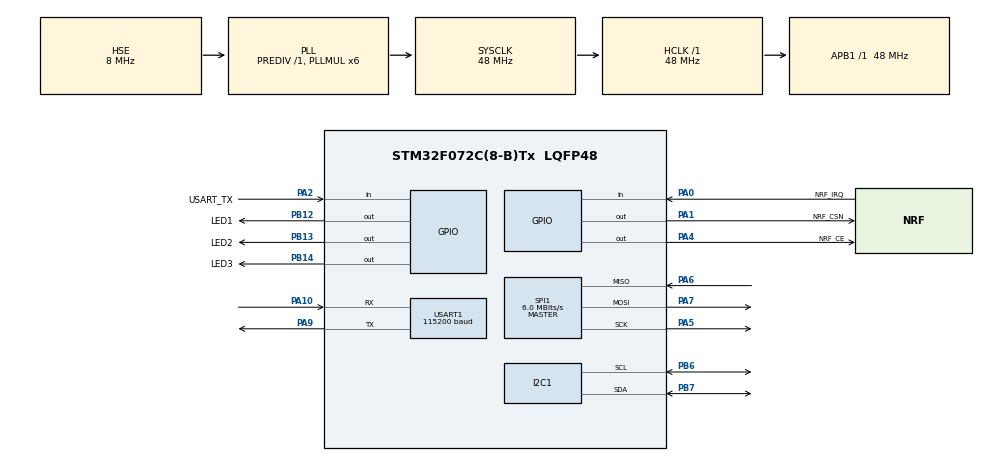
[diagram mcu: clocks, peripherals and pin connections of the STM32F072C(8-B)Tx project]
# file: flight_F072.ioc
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I2C1.Timing=0x20303E5D
Mcu.Family=STM32F0
Mcu.Name=STM32F072C(8-B)Tx
Mcu.Package=LQFP48
NVIC.TIM2_IRQn=true\:1\:0\:true\:false\:true\:true
NVIC.TIM7_IRQn=true\:1\:0\:true\:false\:true\:true
PA0.GPIO_Label=NRF_IRQ
PA0.GPIO_PuPd=GPIO_PULLUP
PA0.Signal=GPIO_Input
PA1.GPIO_Label=NRF_CSN
PA1.GPIO_ModeDefaultOutputPP=GPIO_MODE_OUTPUT_PP
PA1.GPIO_PuPd=GPIO_PULLUP
PA1.GPIO_Speed=GPIO_SPEED_FREQ_HIGH
PA1.PinState=GPIO_PIN_SET
PA1.Signal=GPIO_Output
PA10.Mode=Asynchronous
PA10.Signal=USART1_RX
PA13.Mode=Serial_Wire
PA13.Signal=SYS_SWDIO
PA14.Mode=Serial_Wire
PA14.Signal=SYS_SWCLK
PA2.GPIO_Label=USART_TX
PA2.GPIO_PuPd=GPIO_PULLUP
PA2.Signal=GPIO_Input
PA4.GPIO_Label=NRF_CE
PA4.GPIO_ModeDefaultOutputPP=GPIO_MODE_OUTPUT_PP
PA4.GPIO_PuPd=GPIO_PULLUP
PA4.GPIO_Speed=GPIO_SPEED_FREQ_HIGH
PA4.PinState=GPIO_PIN_SET
PA4.Signal=GPIO_Output
PA5.Mode=Full_Duplex_Master
PA5.Signal=SPI1_SCK
PA6.Mode=Full_Duplex_Master
PA6.Signal=SPI1_MISO
PA7.Mode=Full_Duplex_Master
PA7.Signal=SPI1_MOSI
PA9.Mode=Asynchronous
PA9.Signal=USART1_TX
PB12.GPIO_Label=LED1
PB12.GPIO_PuPd=GPIO_PULLUP
PB12.GPIO_Speed=GPIO_SPEED_FREQ_HIGH
PB12.PinState=GPIO_PIN_SET
PB12.Signal=GPIO_Output
PB13.GPIO_Label=LED2
PB13.GPIO_PuPd=GPIO_PULLUP
PB13.GPIO_Speed=GPIO_SPEED_FREQ_HIGH
PB13.PinState=GPIO_PIN_SET
PB13.Signal=GPIO_Output
PB14.GPIO_Label=LED3
PB14.GPIO_PuPd=GPIO_PULLUP
PB14.GPIO_Speed=GPIO_SPEED_FREQ_HIGH
PB14.PinState=GPIO_PIN_SET
PB14.Signal=GPIO_Output
PB6.GPIO_PuPdOD=GPIO_PULLUP
PB6.Mode=I2C
PB6.Signal=I2C1_SCL
PB7.GPIO_PuPdOD=GPIO_PULLUP
PB7.Mode=I2C
PB7.Signal=I2C1_SDA
PF0-OSC_IN.Mode=HSE-External-Oscillator
PF0-OSC_IN.Signal=RCC_OSC_IN
PF1-OSC_OUT.Mode=HSE-External-Oscillator
PF1-OSC_OUT.Signal=RCC_OSC_OUT
ProjectManager.HeapSize=0x200
ProjectManager.StackSize=0x400
ProjectManager.TargetToolchain=MDK-ARM V5
RCC.AHBFreq_Value=48000000
RCC.APB1Freq_Value=48000000
RCC.APB1TimFreq_Value=48000000
RCC.HCLKFreq_Value=48000000
RCC.I2c1ClockSelection=RCC_I2C1CLKSOURCE_SYSCLK
RCC.PLLMUL=RCC_PLL_MUL6
RCC.PLLSourceVirtual=RCC_PLLSOURCE_HSE
RCC.SYSCLKFreq_VALUE=48000000
RCC.SYSCLKSource=RCC_SYSCLKSOURCE_PLLCLK
SPI1.BaudRatePrescaler=SPI_BAUDRATEPRESCALER_8
SPI1.CalculateBaudRate=6.0 MBits/s
SPI1.DataSize=SPI_DATASIZE_8BIT
SPI1.Direction=SPI_DIRECTION_2LINES
SPI1.Mode=SPI_MODE_MASTER
SPI1.NSSPMode=SPI_NSS_PULSE_DISABLE
SPI1.VirtualType=VM_MASTER
TIM2.AutoReloadPreload=TIM_AUTORELOAD_PRELOAD_ENABLE
TIM2.Period=5000-1
TIM2.Prescaler=48-1
TIM7.AutoReloadPreload=TIM_AUTORELOAD_PRELOAD_ENABLE
TIM7.Period=5000-1
TIM7.Prescaler=4800-1
USART1.BaudRate=115200
USART1.VirtualMode-Asynchronous=VM_ASYNC
VP_TIM2_VS_ClockSourceINT.Mode=Internal
VP_TIM7_VS_ClockSourceINT.Mode=Enable_Timer
board=custom

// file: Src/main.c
/**
  ******************************************************************************
  * @file           : main.c
  * @brief          : Main program body
  ******************************************************************************
  ** This notice applies to any and all portions of this file
  * that are not between comment pairs USER CODE BEGIN and
  * USER CODE END. Other portions of this file, whether
  * inserted by the user or by software development tools
  * are owned by their respective copyright owners.
  *
  * COPYRIGHT(c) 2018 STMicroelectronics
  *
  * Redistribution and use in source and binary forms, with or without modification,
  * are permitted provided that the following conditions are met:
  *   1. Redistributions of source code must retain the above copyright notice,
  *      this list of conditions and the following disclaimer.
  *   2. Redistributions in binary form must reproduce the above copyright notice,
  *      this list of conditions and the following disclaimer in the documentation
  *      and/or other materials provided with the distribution.
  *   3. Neither the name of STMicroelectronics nor the names of its contributors
  *      may be used to endorse or promote products derived from this software
  *      without specific prior written permission.
  *
  * THIS SOFTWARE IS PROVIDED BY THE COPYRIGHT HOLDERS AND CONTRIBUTORS "AS IS"
  * AND ANY EXPRESS OR IMPLIED WARRANTIES, INCLUDING, BUT NOT LIMITED TO, THE
  * IMPLIED WARRANTIES OF MERCHANTABILITY AND FITNESS FOR A PARTICULAR PURPOSE ARE
  * DISCLAIMED. IN NO EVENT SHALL THE COPYRIGHT HOLDER OR CONTRIBUTORS BE LIABLE
  * FOR ANY DIRECT, INDIRECT, INCIDENTAL, SPECIAL, EXEMPLARY, OR CONSEQUENTIAL
  * DAMAGES (INCLUDING, BUT NOT LIMITED TO, PROCUREMENT OF SUBSTITUTE GOODS OR
  * SERVICES; LOSS OF USE, DATA, OR PROFITS; OR BUSINESS INTERRUPTION) HOWEVER
  * CAUSED AND ON ANY THEORY OF LIABILITY, WHETHER IN CONTRACT, STRICT LIABILITY,
  * OR TORT (INCLUDING NEGLIGENCE OR OTHERWISE) ARISING IN ANY WAY OUT OF THE USE
  * OF THIS SOFTWARE, EVEN IF ADVISED OF THE POSSIBILITY OF SUCH DAMAGE.
  *
  ******************************************************************************
  */
#include "main.h"
#include "stm32f0xx_hal.h"
#include "i2c.h"
#include "spi.h"
#include "tim.h"
#include "usart.h"
#include "gpio.h"

/* USER CODE BEGIN Includes */
#include "mpu6050.h"
#include "imu.h"
#include "24l01.h"
/* USER CODE END Includes */

/* USER CODE BEGIN PV */
/* Private variables ---------------------------------------------------------*/
extern  uint8_t Tx_buff[30] ;
/* USER CODE END PV */

void SystemClock_Config(void);

/* USER CODE BEGIN PFP */
/* Private function prototypes -----------------------------------------------*/

/* USER CODE END PFP */

/* USER CODE BEGIN 0 */
uint8_t rx_buf[10]={0}
;/* USER CODE END 0 */

int main(void)
{

  /* MCU Configuration----------------------------------------------------------*/

  /* Reset of all peripherals, Initializes the Flash interface and the Systick. */
  HAL_Init();

  /* Configure the system clock */
  SystemClock_Config();

  /* Initialize all configured peripherals */
  MX_GPIO_Init();
  MX_TIM7_Init();
  MX_TIM2_Init();
  MX_SPI1_Init();
  MX_I2C1_Init();
  MX_USART1_UART_Init();
  /* USER CODE BEGIN 2 */
  HAL_Delay(1000);
  while(mpu6050_init() != 0)
  {
    HAL_GPIO_TogglePin(LED2_GPIO_Port,LED2_Pin);
    HAL_Delay(1000);
  }
//  Get_6050_offest();
//

//  NRF24L01_Init();
//  __HAL_SPI_ENABLE(&hspi1);
//  HAL_Delay(1000);
//  while(NRF24L01_Check() != 0)
//  {
//      HAL_GPIO_WritePin(LED3_GPIO_Port,LED3_Pin,GPIO_PIN_RESET);
//      HAL_Delay(100);
//  }
//  HAL_GPIO_WritePin(LED3_GPIO_Port,LED3_Pin,GPIO_PIN_SET);
//  NRF24L01_RX_Mode();
//
//
////  HAL_TIM_Base_Start_IT(&htim2);
//  HAL_TIM_Base_Start_IT(&htim7);
//
//  Tx_buff[0] = 0xaa;
//  Tx_buff[1] = 0xab;
//  Tx_buff[2] = 0xac;
  /* USER CODE END 2 */

  /* Infinite loop */
  while (1)
  {

  /* USER CODE BEGIN 3 */
//
////        READ_MPU6050();
////        Prepare_6050_Data();
//
//    if(NRF24L01_RxPacket(Tx_buff) == 0)
//    {
//      HAL_GPIO_TogglePin(LED3_GPIO_Port,LED3_Pin);
//    }
////    if(HAL_GPIO_ReadPin(NRF_IRQ_GPIO_Port,NRF_IRQ_Pin))
////    {
////      HAL_GPIO_TogglePin(LED3_GPIO_Port,LED3_Pin);
////      HAL_Delay(1000);
////    }
    HAL_GPIO_TogglePin(LED1_GPIO_Port,LED1_Pin);
    HAL_Delay(500);
    HAL_UART_Transmit(&huart1,"transmit:\n",10,100);
    HAL_UART_Receive(&huart1,rx_buf,10,255);
    HAL_UART_Transmit(&huart1,rx_buf,10,100);
  }
  /* USER CODE END 3 */

}

void SystemClock_Config(void)
{

  RCC_OscInitTypeDef RCC_OscInitStruct;
  RCC_ClkInitTypeDef RCC_ClkInitStruct;
  RCC_PeriphCLKInitTypeDef PeriphClkInit;

    /**Initializes the CPU, AHB and APB busses clocks
    */
  RCC_OscInitStruct.OscillatorType = RCC_OSCILLATORTYPE_HSE;
  RCC_OscInitStruct.HSEState = RCC_HSE_ON;
  RCC_OscInitStruct.PLL.PLLState = RCC_PLL_ON;
  RCC_OscInitStruct.PLL.PLLSource = RCC_PLLSOURCE_HSE;
  RCC_OscInitStruct.PLL.PLLMUL = RCC_PLL_MUL6;
  RCC_OscInitStruct.PLL.PREDIV = RCC_PREDIV_DIV1;
  if (HAL_RCC_OscConfig(&RCC_OscInitStruct) != HAL_OK)
  {
    _Error_Handler(__FILE__, __LINE__);
  }

    /**Initializes the CPU, AHB and APB busses clocks
    */
  RCC_ClkInitStruct.ClockType = RCC_CLOCKTYPE_HCLK|RCC_CLOCKTYPE_SYSCLK
                              |RCC_CLOCKTYPE_PCLK1;
  RCC_ClkInitStruct.SYSCLKSource = RCC_SYSCLKSOURCE_PLLCLK;
  RCC_ClkInitStruct.AHBCLKDivider = RCC_SYSCLK_DIV1;
  RCC_ClkInitStruct.APB1CLKDivider = RCC_HCLK_DIV1;

  if (HAL_RCC_ClockConfig(&RCC_ClkInitStruct, FLASH_LATENCY_1) != HAL_OK)
  {
    _Error_Handler(__FILE__, __LINE__);
  }

  PeriphClkInit.PeriphClockSelection = RCC_PERIPHCLK_USART1|RCC_PERIPHCLK_I2C1;
  PeriphClkInit.Usart1ClockSelection = RCC_USART1CLKSOURCE_PCLK1;
  PeriphClkInit.I2c1ClockSelection = RCC_I2C1CLKSOURCE_SYSCLK;
  if (HAL_RCCEx_PeriphCLKConfig(&PeriphClkInit) != HAL_OK)
  {
    _Error_Handler(__FILE__, __LINE__);
  }

    /**Configure the Systick interrupt time
    */
  HAL_SYSTICK_Config(HAL_RCC_GetHCLKFreq()/1000);

    /**Configure the Systick
    */
  HAL_SYSTICK_CLKSourceConfig(SYSTICK_CLKSOURCE_HCLK);

  /* SysTick_IRQn interrupt configuration */
  HAL_NVIC_SetPriority(SysTick_IRQn, 0, 0);
}

void _Error_Handler(char *file, int line)
{
  while(1)
  {
  }
}

/************************ (C) COPYRIGHT STMicroelectronics *****END OF FILE****/
